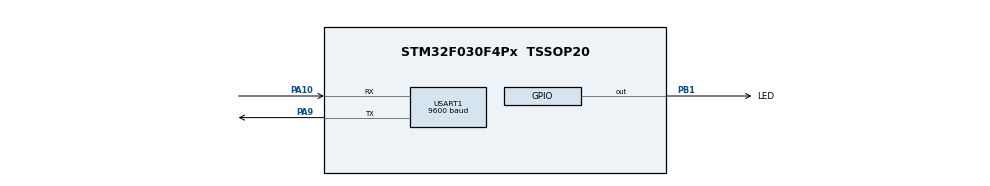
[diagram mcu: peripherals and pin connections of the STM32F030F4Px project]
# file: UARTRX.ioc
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Mcu.Family=STM32F0
Mcu.Name=STM32F030F4Px
Mcu.Package=TSSOP20
PA10.Mode=Asynchronous
PA10.Signal=USART1_RX
PA13.Mode=Serial_Wire
PA13.Signal=SYS_SWDIO
PA14.Mode=Serial_Wire
PA14.Signal=SYS_SWCLK
PA9.Mode=Asynchronous
PA9.Signal=USART1_TX
PB1.GPIO_Label=LED
PB1.Signal=GPIO_Output
ProjectManager.HeapSize=0x200
ProjectManager.StackSize=0x400
ProjectManager.TargetToolchain=MDK-ARM V5.27
USART1.BaudRate=9600
USART1.VirtualMode-Asynchronous=VM_ASYNC
board=custom

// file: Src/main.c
/* USER CODE BEGIN Header */
/**
  ******************************************************************************
  * @file           : main.c
  * @brief          : Main program body
  ******************************************************************************
  * @attention
  *
  * <h2><center>&copy; Copyright (c) 2019 STMicroelectronics.
  * All rights reserved.</center></h2>
  *
  * This software component is licensed by ST under BSD 3-Clause license,
  * the "License"; You may not use this file except in compliance with the
  * License. You may obtain a copy of the License at:
  *                        opensource.org/licenses/BSD-3-Clause
  *
  ******************************************************************************
  */
/* USER CODE END Header */

#include "main.h"

/* USER CODE BEGIN Includes */
#include "stdio.h"
#include "string.h"

/* USER CODE END Includes */

UART_HandleTypeDef huart1;

/* USER CODE BEGIN PV */
char buffer[10];
/* USER CODE END PV */

void SystemClock_Config(void);
static void MX_GPIO_Init(void);
static void MX_USART1_UART_Init(void);

int main(void)
{

  /* MCU Configuration--------------------------------------------------------*/

  /* Reset of all peripherals, Initializes the Flash interface and the Systick. */
  HAL_Init();

  /* Configure the system clock */
  SystemClock_Config();

  /* Initialize all configured peripherals */
  MX_GPIO_Init();
  MX_USART1_UART_Init();

  /* Infinite loop */
  /* USER CODE BEGIN WHILE */
	//memset(buffer, 0, 10);
	//char feedback[] = "received ON\n";

  while (1)
  {
		//HAL_GPIO_WritePin(LED_GPIO_Port, LED_Pin, 1);

		HAL_UART_Receive(&huart1, (uint8_t *)buffer, 10, 1000); // wait a second

		//HAL_UART_Receive(&huart1, (uint8_t *)buffer, 2, HAL_MAX_DELAY);   // wait until get data

//		if (buffer[0] == 'O') {
//			HAL_GPIO_TogglePin(LED_GPIO_Port, LED_Pin);
//
//			//HAL_UART_Transmit(&huart1, (uint8_t *)feedback, sizeof(feedback), 100);
//			HAL_UART_Transmit(&huart1, (uint8_t *)buffer, 2, 100);
//		}

		//HAL_UART_Transmit(&huart1, (uint8_t *)buffer, 2, 100);

		//HAL_UART_Transmit(&huart1, (uint8_t *)"OK\n", 2, 100);

//		if ( buffer[0] == 0x4F ) {
//			HAL_UART_Transmit(&huart1, (uint8_t *)buffer, sizeof(buffer), 100); // send all buffer 10 bytes
//
//			memset(buffer, 0, 10);
//			HAL_GPIO_WritePin(LED_GPIO_Port, LED_Pin, 1);
//		}

		if (strcmp (buffer, "ON") == 0) {
			HAL_UART_Transmit(&huart1, (uint8_t *)buffer, sizeof(buffer), 100); // send all buffer 10 bytes

			memset(buffer, 0, 10);
			HAL_GPIO_WritePin(LED_GPIO_Port, LED_Pin, 1);
			//HAL_GPIO_TogglePin(LED_GPIO_Port, LED_Pin);
			//HAL_UART_Transmit(&huart1, (uint8_t *)buffer, 2, 100);
			//HAL_UART_Transmit(&huart1, (uint8_t *)"OK\n", 3, HAL_MAX_DELAY);
		}

		else if( strcmp (buffer, "OFF") == 0) {
			HAL_UART_Transmit(&huart1, (uint8_t *)buffer, sizeof(buffer), 100); // send all buffer 10 bytes

			memset(buffer, 0, 10);
			HAL_GPIO_WritePin(LED_GPIO_Port, LED_Pin, 0);
		}

		//HAL_Delay(1000);

    /* USER CODE END WHILE */

  }
}

void SystemClock_Config(void)
{
  RCC_OscInitTypeDef RCC_OscInitStruct = {0};
  RCC_ClkInitTypeDef RCC_ClkInitStruct = {0};
  RCC_PeriphCLKInitTypeDef PeriphClkInit = {0};

  /** Initializes the CPU, AHB and APB busses clocks
  */
  RCC_OscInitStruct.OscillatorType = RCC_OSCILLATORTYPE_HSI;
  RCC_OscInitStruct.HSIState = RCC_HSI_ON;
  RCC_OscInitStruct.HSICalibrationValue = RCC_HSICALIBRATION_DEFAULT;
  RCC_OscInitStruct.PLL.PLLState = RCC_PLL_NONE;
  if (HAL_RCC_OscConfig(&RCC_OscInitStruct) != HAL_OK)
  {
    Error_Handler();
  }
  /** Initializes the CPU, AHB and APB busses clocks
  */
  RCC_ClkInitStruct.ClockType = RCC_CLOCKTYPE_HCLK|RCC_CLOCKTYPE_SYSCLK
                              |RCC_CLOCKTYPE_PCLK1;
  RCC_ClkInitStruct.SYSCLKSource = RCC_SYSCLKSOURCE_HSI;
  RCC_ClkInitStruct.AHBCLKDivider = RCC_SYSCLK_DIV1;
  RCC_ClkInitStruct.APB1CLKDivider = RCC_HCLK_DIV1;

  if (HAL_RCC_ClockConfig(&RCC_ClkInitStruct, FLASH_LATENCY_0) != HAL_OK)
  {
    Error_Handler();
  }
  PeriphClkInit.PeriphClockSelection = RCC_PERIPHCLK_USART1;
  PeriphClkInit.Usart1ClockSelection = RCC_USART1CLKSOURCE_PCLK1;
  if (HAL_RCCEx_PeriphCLKConfig(&PeriphClkInit) != HAL_OK)
  {
    Error_Handler();
  }
}

static void MX_USART1_UART_Init(void)
{

  huart1.Instance = USART1;
  huart1.Init.BaudRate = 9600;
  huart1.Init.WordLength = UART_WORDLENGTH_8B;
  huart1.Init.StopBits = UART_STOPBITS_1;
  huart1.Init.Parity = UART_PARITY_NONE;
  huart1.Init.Mode = UART_MODE_TX_RX;
  huart1.Init.HwFlowCtl = UART_HWCONTROL_NONE;
  huart1.Init.OverSampling = UART_OVERSAMPLING_16;
  huart1.Init.OneBitSampling = UART_ONE_BIT_SAMPLE_DISABLE;
  huart1.AdvancedInit.AdvFeatureInit = UART_ADVFEATURE_NO_INIT;
  if (HAL_UART_Init(&huart1) != HAL_OK)
  {
    Error_Handler();
  }

}

static void MX_GPIO_Init(void)
{
  GPIO_InitTypeDef GPIO_InitStruct = {0};

  /* GPIO Ports Clock Enable */
  __HAL_RCC_GPIOB_CLK_ENABLE();
  __HAL_RCC_GPIOA_CLK_ENABLE();

  /*Configure GPIO pin Output Level */
  HAL_GPIO_WritePin(LED_GPIO_Port, LED_Pin, GPIO_PIN_RESET);

  /*Configure GPIO pin : LED_Pin */
  GPIO_InitStruct.Pin = LED_Pin;
  GPIO_InitStruct.Mode = GPIO_MODE_OUTPUT_PP;
  GPIO_InitStruct.Pull = GPIO_NOPULL;
  GPIO_InitStruct.Speed = GPIO_SPEED_FREQ_LOW;
  HAL_GPIO_Init(LED_GPIO_Port, &GPIO_InitStruct);

}

void Error_Handler(void)
{
}

/************************ (C) COPYRIGHT STMicroelectronics *****END OF FILE****/
